# STM32F7x3_v1r0 register map
File version: 1.0
Registers are 32-bit, read-write, reset 0x0 unless marked. A register's access mark holds for its fields unless they carry their own. Offsets are from the block's base; [hi:lo] are bit positions; {n}, {i} and the like mark numbered series.

## C_ADC — Common ADC registers
Base 0x40012300
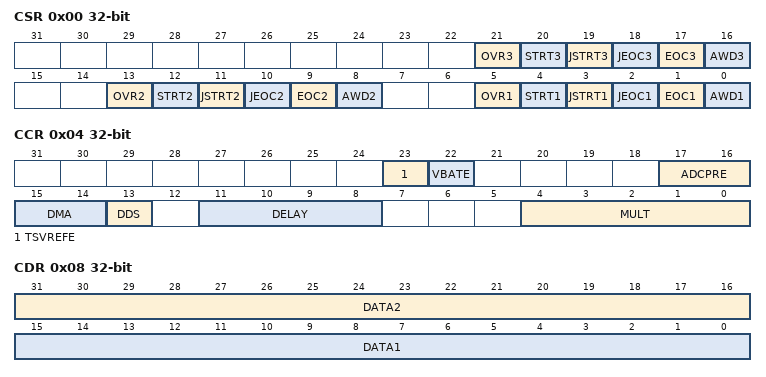
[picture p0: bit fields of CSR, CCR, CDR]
0x00 CSR ro — ADC Common status register
  [21] OVR3 — Overrun flag of ADC3
  [20] STRT3 — Regular channel Start flag of ADC 3
  [19] JSTRT3 — Injected channel Start flag of ADC 3
  [18] JEOC3 — Injected channel end of conversion of ADC 3
  [17] EOC3 — End of conversion of ADC 3
  [16] AWD3 — Analog watchdog flag of ADC 3
  [13] OVR2 — Overrun flag of ADC 2
  [12] STRT2 — Regular channel Start flag of ADC 2
  [11] JSTRT2 — Injected channel Start flag of ADC 2
  [10] JEOC2 — Injected channel end of conversion of ADC 2
  [9] EOC2 — End of conversion of ADC 2
  [8] AWD2 — Analog watchdog flag of ADC 2
  [5] OVR1 — Overrun flag of ADC 1
  [4] STRT1 — Regular channel Start flag of ADC 1
  [3] JSTRT1 — Injected channel Start flag of ADC 1
  [2] JEOC1 — Injected channel end of conversion of ADC 1
  [1] EOC1 — End of conversion of ADC 1
  [0] AWD1 — Analog watchdog flag of ADC 1
0x04 CCR — ADC common control register
  [23] TSVREFE — Temperature sensor and VREFINT enable
  [22] VBATE — VBAT enable
  [17:16] ADCPRE — ADC prescaler
  [15:14] DMA — Direct memory access mode for multi ADC mode
  [13] DDS — DMA disable selection for multi-ADC mode
  [11:8] DELAY — Delay between 2 sampling phases
  [4:0] MULT — Multi ADC mode selection
0x08 CDR ro — ADC common regular data register for dual and triple modes
  [31:16] DATA2 — 2nd data item of a pair of regular conversions
  [15:0] DATA1 — 1st data item of a pair of regular conversions

## CRC — Cryptographic processor
Base 0x40023000
0x00 DR reset 0xFFFFFFFF — Data register
  [31:0] DR — Data Register
0x04 IDR — Independent Data register
  [7:0] IDR
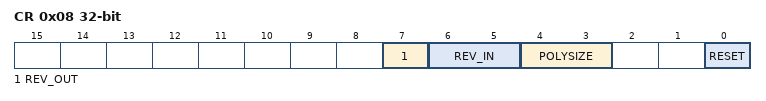
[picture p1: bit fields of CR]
0x08 CR wo — Control register
  [7] REV_OUT — Reverse output data
  [6:5] REV_IN — Reverse input data
  [4:3] POLYSIZE — Polynomial size
  [0] RESET — RESET bit
0x10 INIT — Initial CRC value
  [31:0] CRC_INIT — Programmable initial CRC value
0x14 POL — CRC polynomial
  [31:0] POL — Programmable polynomial

## CRYP — Cryptographic processor
Base 0x50060000
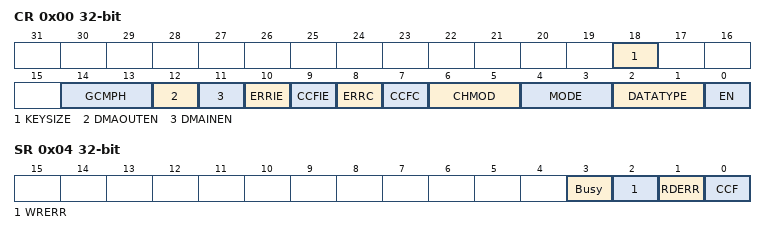
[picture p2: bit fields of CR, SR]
0x00 CR — control register
  [18] KEYSIZE — Key size selection
  [14:13] GCMPH — Used only for GCM, GMAC and CMAC algorithms and has no effect when other
  [12] DMAOUTEN — Enable DMA management of data output phase
  [11] DMAINEN — Enable DMA management of data input phase
  [10] ERRIE — Error interrupt enable
  [9] CCFIE — CCF flag interrupt enable
  [8] ERRC — Error clear
  [7] CCFC — Computation complete flag clear
  [6:5] CHMOD — AES chaining mode
  [4:3] MODE — AES operating mode
  [2:1] DATATYPE — Data type selection (for data in and data out to/from the cryptographic block)
  [0] EN — AES enable
0x04 SR ro — status register
  [3] Busy — Busy flag
  [2] WRERR — Write error flag
  [1] RDERR — Read error flag
  [0] CCF — Computation complete flag
0x08 DINR — data input register
  [31:0] DINR — Data input
0x0C DOUTR ro — data output register
  [31:0] DOUTR — Data output
0x10 KEYR0 — key register
  [30:0] KEYR0 — Data output register
0x14 KEYR1 — key register
  [31:0] KEYR1 — Data output register
0x18 KEYR2 ro — key register
  [30:0] KEYR2 — Data output register
0x1C KEYR3 ro — key register
  [31:0] KEYR3 — Data output register
0x20 IVR0 — initialization vector register
{0x20+4i} IVR{i} (i=1..3) — initialization vector register
  [31:0] IVR{i} — Initialization vector register
{0x20+4i} KEYR{i} (i=4..7) — key registers
  [31:0] KEYR{i} — Data output register
{0x40+4i} SUSP{i}R (i=0..2) — Suspend registers
  [31:0] SUSP{i}R — AES Suspend
0x4C SUSP3R — Suspend registers
  [31:0] SUSP3R — IV127
{0x40+4i} SUSP{i}R (i=4..7) — Suspend registers
  [31:0] SUSP{i}R — AES Suspend

## DBG — Debug support
Base 0xE0042000
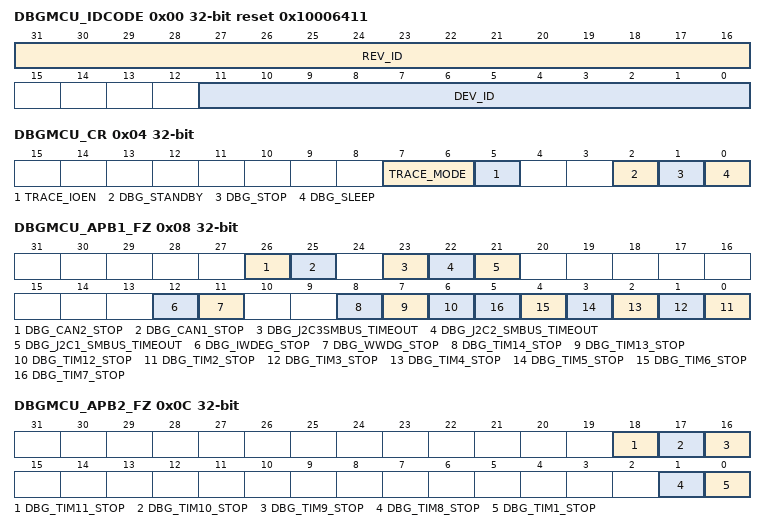
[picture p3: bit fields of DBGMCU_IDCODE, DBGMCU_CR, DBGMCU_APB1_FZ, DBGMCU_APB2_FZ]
0x00 DBGMCU_IDCODE ro reset 0x10006411 — IDCODE
  [31:16] REV_ID, [11:0] DEV_ID
0x04 DBGMCU_CR — Control Register
  [7:6] TRACE_MODE, [5] TRACE_IOEN, [2] DBG_STANDBY, [1] DBG_STOP, [0] DBG_SLEEP
0x08 DBGMCU_APB1_FZ — Debug MCU APB1 Freeze registe
  [26] DBG_CAN2_STOP, [25] DBG_CAN1_STOP, [23] DBG_J2C3SMBUS_TIMEOUT, [22] DBG_J2C2_SMBUS_TIMEOUT, [21] DBG_J2C1_SMBUS_TIMEOUT, [12] DBG_IWDEG_STOP, [11] DBG_WWDG_STOP, [8] DBG_TIM14_STOP, [7] DBG_TIM13_STOP, [6] DBG_TIM12_STOP, [n-2] DBG_TIM{n}_STOP (n=2..7)
0x0C DBGMCU_APB2_FZ — Debug MCU APB2 Freeze registe
  [18] DBG_TIM11_STOP — TIM11 counter stopped when core is halted
  [17] DBG_TIM10_STOP — TIM10 counter stopped when core is halted
  [16] DBG_TIM9_STOP — TIM9 counter stopped when core is halted
  [1] DBG_TIM8_STOP — TIM8 counter stopped when core is halted
  [0] DBG_TIM1_STOP — TIM1 counter stopped when core is halted
